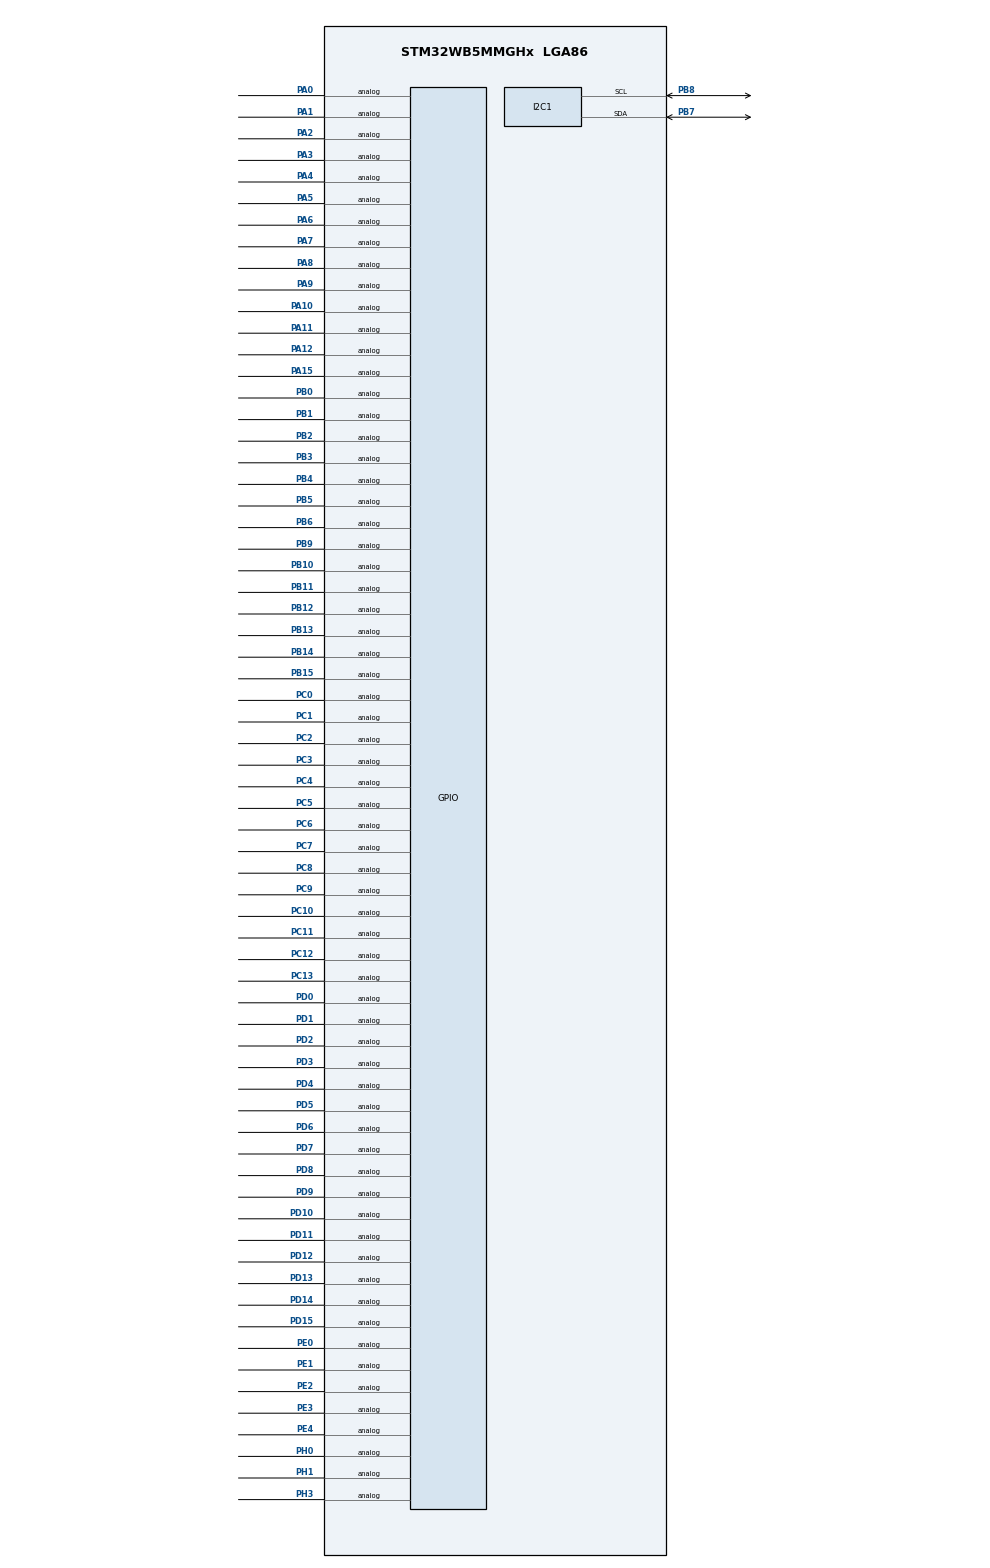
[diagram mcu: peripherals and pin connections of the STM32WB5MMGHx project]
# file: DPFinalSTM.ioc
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ANT_IN.Signal=GPIO_Analog
ANT_NC.Signal=GPIO_Analog
I2C1.Timing=0x10B17DB5
Mcu.Family=STM32WB
Mcu.Name=STM32WB5MMGHx
Mcu.Package=LGA86
NVIC.HSEM_IRQn=true\:0\:0\:false\:false\:true\:false\:true\:true
NVIC.IPCC_C1_RX_IRQn=true\:0\:0\:false\:false\:true\:true\:true\:true
NVIC.IPCC_C1_TX_IRQn=true\:0\:0\:false\:false\:true\:true\:true\:true
NVIC.PriorityGroup=NVIC_PRIORITYGROUP_4
NVIC.RCC_IRQn=true\:0\:0\:false\:false\:true\:true\:false\:true
NVIC.RTC_WKUP_IRQn=true\:0\:0\:false\:false\:true\:true\:true\:true
PA0.Signal=GPIO_Analog
PA1.Signal=GPIO_Analog
PA10.Signal=GPIO_Analog
PA11.Signal=GPIO_Analog
PA12.Signal=GPIO_Analog
PA13.Mode=Serial_Wire
PA13.Signal=SYS_JTMS-SWDIO
PA14.Mode=Serial_Wire
PA14.Signal=SYS_JTCK-SWCLK
PA15.Signal=GPIO_Analog
PA2.Signal=GPIO_Analog
PA3.Signal=GPIO_Analog
PA4.Signal=GPIO_Analog
PA5.Signal=GPIO_Analog
PA6.Signal=GPIO_Analog
PA7.Signal=GPIO_Analog
PA8.Signal=GPIO_Analog
PA9.Signal=GPIO_Analog
PB0.Signal=GPIO_Analog
PB1.Signal=GPIO_Analog
PB10.Signal=GPIO_Analog
PB11.Signal=GPIO_Analog
PB12.Signal=GPIO_Analog
PB13.Signal=GPIO_Analog
PB14.Signal=GPIO_Analog
PB15.Signal=GPIO_Analog
PB2.Signal=GPIO_Analog
PB3.Signal=GPIO_Analog
PB4.Signal=GPIO_Analog
PB5.Signal=GPIO_Analog
PB6.Signal=GPIO_Analog
PB7.GPIO_Pu=GPIO_PULLUP
PB7.Mode=I2C
PB7.Signal=I2C1_SDA
PB8.GPIO_Pu=GPIO_PULLUP
PB8.Mode=I2C
PB8.Signal=I2C1_SCL
PB9.Signal=GPIO_Analog
PC0.Signal=GPIO_Analog
PC1.Signal=GPIO_Analog
PC10.Signal=GPIO_Analog
PC11.Signal=GPIO_Analog
PC12.Signal=GPIO_Analog
PC13.Signal=GPIO_Analog
PC2.Signal=GPIO_Analog
PC3.Signal=GPIO_Analog
PC4.Signal=GPIO_Analog
PC5.Signal=GPIO_Analog
PC6.Signal=GPIO_Analog
PC7.Signal=GPIO_Analog
PC8.Signal=GPIO_Analog
PC9.Signal=GPIO_Analog
PD0.Signal=GPIO_Analog
PD1.Signal=GPIO_Analog
PD10.Signal=GPIO_Analog
PD11.Signal=GPIO_Analog
PD12.Signal=GPIO_Analog
PD13.Signal=GPIO_Analog
PD14.Signal=GPIO_Analog
PD15.Signal=GPIO_Analog
PD2.Signal=GPIO_Analog
PD3.Signal=GPIO_Analog
PD4.Signal=GPIO_Analog
PD5.Signal=GPIO_Analog
PD6.Signal=GPIO_Analog
PD7.Signal=GPIO_Analog
PD8.Signal=GPIO_Analog
PD9.Signal=GPIO_Analog
PE0.Signal=GPIO_Analog
PE1.Signal=GPIO_Analog
PE2.Signal=GPIO_Analog
PE3.Signal=GPIO_Analog
PE4.Signal=GPIO_Analog
PH0.Signal=GPIO_Analog
PH1.Signal=GPIO_Analog
PH3-BOOT0.Signal=GPIO_Analog
ProjectManager.HeapSize=0x200
ProjectManager.StackSize=0x400
ProjectManager.TargetToolchain=STM32CubeIDE
RCC.AHB2CLKDivider=RCC_SYSCLK_DIV2
RCC.AHBFreq_Value=64000000
RCC.APB1Freq_Value=64000000
RCC.APB1TimFreq_Value=64000000
RCC.APB2Freq_Value=64000000
RCC.APB2TimFreq_Value=64000000
RCC.APB3Freq_Value=16000000
RCC.CortexFreq_Value=64000000
RCC.HCLKFreq_Value=64000000
RCC.HSE_VALUE=32000000
RCC.HSI48_VALUE=48000000
RCC.HSI_VALUE=16000000
RCC.PLLN=32
RCC.SYSCLKFreq_VALUE=64000000
RCC.SYSCLKSource=RCC_SYSCLKSOURCE_PLLCLK
RCC.VCOOutputFreq_Value=128000000
RF_OUT.Signal=GPIO_Analog
STM32_WPAN.AD_TYPE_COMPLETE_LOCAL_NAME=BalodiHeart
STM32_WPAN.AD_TYPE_COMPLETE_LOCAL_NAME_LENGTH=12
STM32_WPAN.BLE_CFG_CLT_MAX_NBR_CB=5
STM32_WPAN.CFG_BLE_ATT_VALUE_ARRAY_SIZE=6000
STM32_WPAN.CFG_BLE_MAX_ATT_MTU=500
STM32_WPAN.CFG_HW_TS_MAX_NBR_CONCURRENT_TIMER=10
STM32_WPAN.CFG_HW_TS_NVIC_RTC_WAKEUP_IT_PREEMPTPRIO=0
STM32_WPAN.CFG_LPM_SUPPORTED=0
STM32_WPAN.CFG_LSCLK_LSE=0
STM32_WPAN.CFG_USE_SMPS=1
STM32_WPAN.CUSTOM_P2P_SERVER=Disabled
STM32_WPAN.CUSTOM_TEMPLATE=Enabled
STM32_WPAN.INCLUDE_AD_TYPE_COMPLETE_LOCAL_NAME=1
STM32_WPAN.INCLUDE_AD_TYPE_MANUFACTURER_SPECIFIC_DATA=1
STM32_WPAN.INCLUDE_AD_TYPE_TX_POWER_LEVEL=1
STM32_WPAN.LOCAL_NAME=BalodiK
STM32_WPAN.LOCAL_NAME_FORMATTED=,'B','a','l','o','d','i','K'
STM32_WPAN.NUMBER_OF_SERVICES=1
STM32_WPAN.PAIRING_PARAMETERS=OFF
STM32_WPAN.SERVICE1_CHAR1_LONG_NAME=BalodiHeartWave
STM32_WPAN.SERVICE1_CHAR1_PROP_INDICATE=CHAR_PROP_INDICATE
STM32_WPAN.SERVICE1_CHAR1_PROP_NOTIFY=CHAR_PROP_NOTIFY
STM32_WPAN.SERVICE1_CHAR1_PROP_READ=CHAR_PROP_READ
STM32_WPAN.SERVICE1_CHAR1_PROP_WRITE=CHAR_PROP_WRITE
STM32_WPAN.SERVICE1_CHAR1_PROP_WRITE_WITHOUT_RESP=CHAR_PROP_WRITE_WITHOUT_RESP
STM32_WPAN.SERVICE1_CHAR1_SHORT_NAME=BHW
STM32_WPAN.SERVICE1_CHAR1_UUID=00 10
STM32_WPAN.SERVICE1_CHAR1_UUID_TYPE=0x01
STM32_WPAN.SERVICE1_CHAR1_VALUE_LENGTH=300
STM32_WPAN.SERVICE1_CHAR2_LONG_NAME=BalodiHeartRate
STM32_WPAN.SERVICE1_CHAR2_PROP_INDICATE=CHAR_PROP_INDICATE
STM32_WPAN.SERVICE1_CHAR2_PROP_NOTIFY=CHAR_PROP_NOTIFY
STM32_WPAN.SERVICE1_CHAR2_PROP_READ=CHAR_PROP_READ
STM32_WPAN.SERVICE1_CHAR2_PROP_WRITE=CHAR_PROP_WRITE
STM32_WPAN.SERVICE1_CHAR2_PROP_WRITE_WITHOUT_RESP=CHAR_PROP_WRITE_WITHOUT_RESP
STM32_WPAN.SERVICE1_CHAR2_SHORT_NAME=BHR
STM32_WPAN.SERVICE1_CHAR2_UUID=00 01
STM32_WPAN.SERVICE1_CHAR3_LONG_NAME=BalodiHRV
STM32_WPAN.SERVICE1_CHAR3_PROP_INDICATE=CHAR_PROP_INDICATE
STM32_WPAN.SERVICE1_CHAR3_PROP_NOTIFY=CHAR_PROP_NOTIFY
STM32_WPAN.SERVICE1_CHAR3_PROP_READ=CHAR_PROP_READ
STM32_WPAN.SERVICE1_CHAR3_PROP_WRITE=CHAR_PROP_WRITE
STM32_WPAN.SERVICE1_CHAR3_PROP_WRITE_WITHOUT_RESP=CHAR_PROP_WRITE_WITHOUT_RESP
STM32_WPAN.SERVICE1_CHAR3_SHORT_NAME=BHRV
STM32_WPAN.SERVICE1_CHAR3_UUID=00 02
STM32_WPAN.SERVICE1_CHAR3_VALUE_LENGTH=50
STM32_WPAN.SERVICE1_LONG_NAME=BalodiHeart
STM32_WPAN.SERVICE1_NUMBER_OF_CHARACTERISTICS=3
STM32_WPAN.SERVICE1_SHORT_NAME=BH
STM32_WPAN.SERVICE1_UUID=00 01
STM32_WPAN.SERVICE1_UUID_TYPE=0x01
VP_HSEM_VS_HSEM.Mode=HSEM_Activate
VP_IPCC_VS_IPCC.Mode=IPCC_Activate
VP_MEMORYMAP_VS_MEMORYMAP.Mode=CurAppReg
VP_RCC_V_OSC32_IN.Mode=LSE-External-Clock-Source
VP_RCC_V_OSC_IN.Mode=HSE-External-Clock-Source
VP_RF_VS_RF.Mode=RF_Activate
VP_RTC_VS_RTC_Activate.Mode=RTC_Enabled
VP_RTC_VS_RTC_WakeUp_intern.Mode=WakeUp
VP_SEQUENCER_VS_SEQUENCER.Mode=SEQUENCER_Enabled
VP_STM32_WPAN_VS_BLE_HOST.Mode=STM32_WPAN_Enabled
VP_TINY_LPM_VS_TINY_LPM.Mode=TINY_LPM_Enabled
board=custom

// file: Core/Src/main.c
/* USER CODE BEGIN Header */
/**
  ******************************************************************************
  * @file           : main.c
  * @brief          : Main program body
  ******************************************************************************
  * @attention
  *
  * Copyright (c) 2025 STMicroelectronics.
  * All rights reserved.
  *
  * This software is licensed under terms that can be found in the LICENSE file
  * in the root directory of this software component.
  * If no LICENSE file comes with this software, it is provided AS-IS.
  *
  ******************************************************************************
  */
/* USER CODE END Header */
#include "main.h"

/* USER CODE BEGIN Includes */
#include "ADPD1080.h"
#include "ADP1080_REG_GEN.h"
#include "custom_app.h"
//#include "LSM6DSLTR.h"
#include "stm32_lpm.h"
#include "LSM6DSL.h"
/* USER CODE END Includes */

/* USER CODE BEGIN PD */
#define ADPD1080_REG_ADDR      0x14        // Register address to write
#define VALUE_TO_WRITE         0x0557      // 16-bit value to write

/* USER CODE END PD */

I2C_HandleTypeDef hi2c1;

IPCC_HandleTypeDef hipcc;

RTC_HandleTypeDef hrtc;

/* USER CODE BEGIN PV */

HAL_I2C_StateTypeDef state;
HAL_StatusTypeDef i2cStatus;
volatile int32_t count=0;
uint8_t reg_data[2];
volatile uint16_t read_value = 0;
uint8_t register_value2[2] ;

/* USER CODE END PV */

void SystemClock_Config(void);
void PeriphCommonClock_Config(void);
static void MX_RF_Init(void);
static void MX_GPIO_Init(void);
static void MX_IPCC_Init(void);
static void MX_RTC_Init(void);
static void MX_I2C1_Init(void);
/* USER CODE BEGIN PFP */
void Custom( void );

/* USER CODE END PFP */

int main(void)
{

  /* MCU Configuration--------------------------------------------------------*/

  /* Reset of all peripherals, Initializes the Flash interface and the Systick. */
  HAL_Init();
  /* Config code for STM32_WPAN (HSE Tuning must be done before system clock configuration) */
  MX_APPE_Config();

  /* Configure the system clock */
  SystemClock_Config();

  /* Configure the peripherals common clocks */
  PeriphCommonClock_Config();

  /* IPCC initialisation */
  MX_IPCC_Init();

  /* Initialize all configured peripherals */
  MX_RF_Init();
  MX_GPIO_Init();
  MX_RTC_Init();
  MX_I2C1_Init();
  /* USER CODE BEGIN 2 */
  ADPD1080_ReadAllRegisters(&hi2c1);
  ADPD1080_CheckRegisters(&hi2c1);
  HAL_I2C_Mem_Read(&hi2c1, ADPD1080_ADDR, 0x14, I2C_MEMADD_SIZE_8BIT, reg_data, 2, HAL_MAX_DELAY);
  //HAL_I2C_Mem_Read(&hi2c1, LSM6DSL_ADDR, 0x11, I2C_MEMADD_SIZE_8BIT, register_value2, 2, HAL_MAX_DELAY);

  HAL_Delay(1000);

  /* USER CODE END 2 */

  /* Init code for STM32_WPAN */
  MX_APPE_Init();

  /* Infinite loop */
  while (1)
  {
    //MX_APPE_Process();

  }
}

void SystemClock_Config(void)
{
  RCC_OscInitTypeDef RCC_OscInitStruct = {0};
  RCC_ClkInitTypeDef RCC_ClkInitStruct = {0};

  /** Configure the main internal regulator output voltage
  */
  __HAL_PWR_VOLTAGESCALING_CONFIG(PWR_REGULATOR_VOLTAGE_SCALE1);

  /** Initializes the RCC Oscillators according to the specified parameters
  * in the RCC_OscInitTypeDef structure.
  */
  RCC_OscInitStruct.OscillatorType = RCC_OSCILLATORTYPE_HSI|RCC_OSCILLATORTYPE_LSI1
                              |RCC_OSCILLATORTYPE_HSE|RCC_OSCILLATORTYPE_MSI;
  RCC_OscInitStruct.HSEState = RCC_HSE_ON;
  RCC_OscInitStruct.HSIState = RCC_HSI_ON;
  RCC_OscInitStruct.MSIState = RCC_MSI_ON;
  RCC_OscInitStruct.HSICalibrationValue = RCC_HSICALIBRATION_DEFAULT;
  RCC_OscInitStruct.MSICalibrationValue = RCC_MSICALIBRATION_DEFAULT;
  RCC_OscInitStruct.MSIClockRange = RCC_MSIRANGE_6;
  RCC_OscInitStruct.LSIState = RCC_LSI_ON;
  RCC_OscInitStruct.PLL.PLLState = RCC_PLL_ON;
  RCC_OscInitStruct.PLL.PLLSource = RCC_PLLSOURCE_MSI;
  RCC_OscInitStruct.PLL.PLLM = RCC_PLLM_DIV1;
  RCC_OscInitStruct.PLL.PLLN = 32;
  RCC_OscInitStruct.PLL.PLLP = RCC_PLLP_DIV2;
  RCC_OscInitStruct.PLL.PLLR = RCC_PLLR_DIV2;
  RCC_OscInitStruct.PLL.PLLQ = RCC_PLLQ_DIV2;
  if (HAL_RCC_OscConfig(&RCC_OscInitStruct) != HAL_OK)
  {
    Error_Handler();
  }

  /** Configure the SYSCLKSource, HCLK, PCLK1 and PCLK2 clocks dividers
  */
  RCC_ClkInitStruct.ClockType = RCC_CLOCKTYPE_HCLK4|RCC_CLOCKTYPE_HCLK2
                              |RCC_CLOCKTYPE_HCLK|RCC_CLOCKTYPE_SYSCLK
                              |RCC_CLOCKTYPE_PCLK1|RCC_CLOCKTYPE_PCLK2;
  RCC_ClkInitStruct.SYSCLKSource = RCC_SYSCLKSOURCE_PLLCLK;
  RCC_ClkInitStruct.AHBCLKDivider = RCC_SYSCLK_DIV1;
  RCC_ClkInitStruct.APB1CLKDivider = RCC_HCLK_DIV1;
  RCC_ClkInitStruct.APB2CLKDivider = RCC_HCLK_DIV1;
  RCC_ClkInitStruct.AHBCLK2Divider = RCC_SYSCLK_DIV2;
  RCC_ClkInitStruct.AHBCLK4Divider = RCC_SYSCLK_DIV1;

  if (HAL_RCC_ClockConfig(&RCC_ClkInitStruct, FLASH_LATENCY_3) != HAL_OK)
  {
    Error_Handler();
  }
}

void PeriphCommonClock_Config(void)
{
  RCC_PeriphCLKInitTypeDef PeriphClkInitStruct = {0};

  /** Initializes the peripherals clock
  */
  PeriphClkInitStruct.PeriphClockSelection = RCC_PERIPHCLK_SMPS|RCC_PERIPHCLK_RFWAKEUP;
  PeriphClkInitStruct.RFWakeUpClockSelection = RCC_RFWKPCLKSOURCE_HSE_DIV1024;
  PeriphClkInitStruct.SmpsClockSelection = RCC_SMPSCLKSOURCE_HSI;
  PeriphClkInitStruct.SmpsDivSelection = RCC_SMPSCLKDIV_RANGE1;

  if (HAL_RCCEx_PeriphCLKConfig(&PeriphClkInitStruct) != HAL_OK)
  {
    Error_Handler();
  }
}

static void MX_I2C1_Init(void)
{

  hi2c1.Instance = I2C1;
  hi2c1.Init.Timing = 0x10B17DB5;
  hi2c1.Init.OwnAddress1 = 0;
  hi2c1.Init.AddressingMode = I2C_ADDRESSINGMODE_7BIT;
  hi2c1.Init.DualAddressMode = I2C_DUALADDRESS_DISABLE;
  hi2c1.Init.OwnAddress2 = 0;
  hi2c1.Init.OwnAddress2Masks = I2C_OA2_NOMASK;
  hi2c1.Init.GeneralCallMode = I2C_GENERALCALL_DISABLE;
  hi2c1.Init.NoStretchMode = I2C_NOSTRETCH_DISABLE;
  if (HAL_I2C_Init(&hi2c1) != HAL_OK)
  {
    Error_Handler();
  }

  /** Configure Analogue filter
  */
  if (HAL_I2CEx_ConfigAnalogFilter(&hi2c1, I2C_ANALOGFILTER_ENABLE) != HAL_OK)
  {
    Error_Handler();
  }

  /** Configure Digital filter
  */
  if (HAL_I2CEx_ConfigDigitalFilter(&hi2c1, 0) != HAL_OK)
  {
    Error_Handler();
  }

}

static void MX_IPCC_Init(void)
{

  hipcc.Instance = IPCC;
  if (HAL_IPCC_Init(&hipcc) != HAL_OK)
  {
    Error_Handler();
  }

}

static void MX_RF_Init(void)
{

}

static void MX_RTC_Init(void)
{

  /** Initialize RTC Only
  */
  hrtc.Instance = RTC;
  hrtc.Init.HourFormat = RTC_HOURFORMAT_24;
  hrtc.Init.AsynchPrediv = CFG_RTC_ASYNCH_PRESCALER;
  hrtc.Init.SynchPrediv = CFG_RTC_SYNCH_PRESCALER;
  hrtc.Init.OutPut = RTC_OUTPUT_DISABLE;
  hrtc.Init.OutPutPolarity = RTC_OUTPUT_POLARITY_HIGH;
  hrtc.Init.OutPutType = RTC_OUTPUT_TYPE_OPENDRAIN;
  hrtc.Init.OutPutRemap = RTC_OUTPUT_REMAP_NONE;
  if (HAL_RTC_Init(&hrtc) != HAL_OK)
  {
    Error_Handler();
  }

  /** Enable the WakeUp
  */
  if (HAL_RTCEx_SetWakeUpTimer_IT(&hrtc, 0, RTC_WAKEUPCLOCK_RTCCLK_DIV16) != HAL_OK)
  {
    Error_Handler();
  }

}

static void MX_GPIO_Init(void)
{
  GPIO_InitTypeDef GPIO_InitStruct = {0};

  /* GPIO Ports Clock Enable */
  __HAL_RCC_GPIOA_CLK_ENABLE();
  __HAL_RCC_GPIOC_CLK_ENABLE();
  __HAL_RCC_GPIOB_CLK_ENABLE();
  __HAL_RCC_GPIOH_CLK_ENABLE();
  __HAL_RCC_GPIOD_CLK_ENABLE();
  __HAL_RCC_GPIOE_CLK_ENABLE();

  /*Configure GPIO pins : PA2 PA1 PA0 PA15
                           PA10 PA12 PA11 PA8
                           PA9 PA7 PA6 PA5
                           PA4 PA3 */
  GPIO_InitStruct.Pin = GPIO_PIN_2|GPIO_PIN_1|GPIO_PIN_0|GPIO_PIN_15
                          |GPIO_PIN_10|GPIO_PIN_12|GPIO_PIN_11|GPIO_PIN_8
                          |GPIO_PIN_9|GPIO_PIN_7|GPIO_PIN_6|GPIO_PIN_5
                          |GPIO_PIN_4|GPIO_PIN_3;
  GPIO_InitStruct.Mode = GPIO_MODE_ANALOG;
  GPIO_InitStruct.Pull = GPIO_NOPULL;
  HAL_GPIO_Init(GPIOA, &GPIO_InitStruct);

  /*Configure GPIO pins : PC3 PC2 PC1 PC0
                           PC10 PC11 PC12 PC6
                           PC13 PC5 PC4 PC9
                           PC7 PC8 */
  GPIO_InitStruct.Pin = GPIO_PIN_3|GPIO_PIN_2|GPIO_PIN_1|GPIO_PIN_0
                          |GPIO_PIN_10|GPIO_PIN_11|GPIO_PIN_12|GPIO_PIN_6
                          |GPIO_PIN_13|GPIO_PIN_5|GPIO_PIN_4|GPIO_PIN_9
                          |GPIO_PIN_7|GPIO_PIN_8;
  GPIO_InitStruct.Mode = GPIO_MODE_ANALOG;
  GPIO_InitStruct.Pull = GPIO_NOPULL;
  HAL_GPIO_Init(GPIOC, &GPIO_InitStruct);

  /*Configure GPIO pins : PB9 PB5 PB4 PB3
                           PB13 PB14 PB15 PB6
                           PB12 PB1 PB0 PB11
                           PB10 PB2 */
  GPIO_InitStruct.Pin = GPIO_PIN_9|GPIO_PIN_5|GPIO_PIN_4|GPIO_PIN_3
                          |GPIO_PIN_13|GPIO_PIN_14|GPIO_PIN_15|GPIO_PIN_6
                          |GPIO_PIN_12|GPIO_PIN_1|GPIO_PIN_0|GPIO_PIN_11
                          |GPIO_PIN_10|GPIO_PIN_2;
  GPIO_InitStruct.Mode = GPIO_MODE_ANALOG;
  GPIO_InitStruct.Pull = GPIO_NOPULL;
  HAL_GPIO_Init(GPIOB, &GPIO_InitStruct);

  /*Configure GPIO pins : PH3 PH0 PH1 */
  GPIO_InitStruct.Pin = GPIO_PIN_3|GPIO_PIN_0|GPIO_PIN_1;
  GPIO_InitStruct.Mode = GPIO_MODE_ANALOG;
  GPIO_InitStruct.Pull = GPIO_NOPULL;
  HAL_GPIO_Init(GPIOH, &GPIO_InitStruct);

  /*Configure GPIO pins : PD0 PD1 PD14 PD13
                           PD12 PD7 PD2 PD3
                           PD4 PD9 PD8 PD15
                           PD10 PD5 PD6 PD11 */
  GPIO_InitStruct.Pin = GPIO_PIN_0|GPIO_PIN_1|GPIO_PIN_14|GPIO_PIN_13
                          |GPIO_PIN_12|GPIO_PIN_7|GPIO_PIN_2|GPIO_PIN_3
                          |GPIO_PIN_4|GPIO_PIN_9|GPIO_PIN_8|GPIO_PIN_15
                          |GPIO_PIN_10|GPIO_PIN_5|GPIO_PIN_6|GPIO_PIN_11;
  GPIO_InitStruct.Mode = GPIO_MODE_ANALOG;
  GPIO_InitStruct.Pull = GPIO_NOPULL;
  HAL_GPIO_Init(GPIOD, &GPIO_InitStruct);

  /*Configure GPIO pins : PE4 PE1 PE3 PE2
                           PE0 */
  GPIO_InitStruct.Pin = GPIO_PIN_4|GPIO_PIN_1|GPIO_PIN_3|GPIO_PIN_2
                          |GPIO_PIN_0;
  GPIO_InitStruct.Mode = GPIO_MODE_ANALOG;
  GPIO_InitStruct.Pull = GPIO_NOPULL;
  HAL_GPIO_Init(GPIOE, &GPIO_InitStruct);

}

void Error_Handler(void)
{
  __disable_irq();
  while (1)
  {
  }
}
